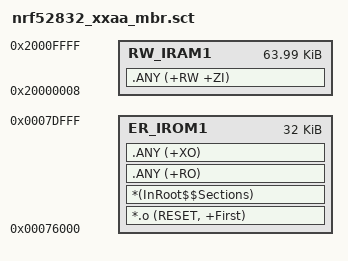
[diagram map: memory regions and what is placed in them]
; *************************************************************
; *** Scatter-Loading Description File generated by uVision ***
; *************************************************************

LR_IROM1 0x00076000 0x00008000  {    ; load region size_region
  ER_IROM1 0x00076000 0x00008000  {  ; load address = execution address
   *.o (RESET, +First)
   *(InRoot$$Sections)
   .ANY (+RO)
   .ANY (+XO)
  }
  RW_IRAM1 0x20000008 0x0000FFF8  {  ; RW data
   .ANY (+RW +ZI)
  }
}

